# Watchdog register map
Vendor: Texas Instruments
Peripheral module from a debugger description file (folder am335x).
Registers are 32-bit, read-write, no defined reset value unless marked. A register's access mark holds for its fields unless they carry their own. Offsets are as the file gives them; lines under a group give offsets from that group; [hi:lo] are bit positions; {n}, {i} and the like mark numbered series; 'fields as' and 'values as' point back to an identical list; <NAME> marks a mode.

## WATCHDOG_TIMER
0x00 WDT_WIDR ro — Watchdog Identification Register
  [31:0] REVISION — IP Revision
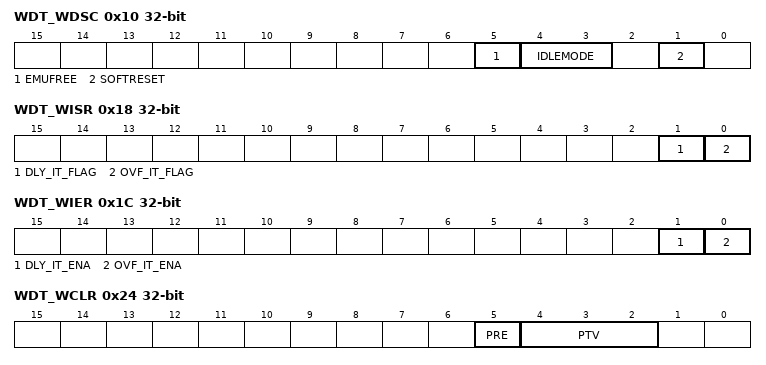
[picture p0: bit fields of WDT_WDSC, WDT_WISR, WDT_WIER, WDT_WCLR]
0x10 WDT_WDSC access per field — The Watchdog System Control Register controls the various parameters of the L4 interface.
  [5] EMUFREE rw — Emulation mode
  [4:3] IDLEMODE rw — Configuration of the local target state management mode.By definition, target can handle read/write transaction as long as it is out of IDLE state.
  [1] SOFTRESET rw — Software reset. (Optional)
0x14 WDT_WDST ro — The Watchdog Status Register provides status information about the module.
  [0] RESETDONE — Internal module reset monitoring
0x18 WDT_WISR access per field — The Watchdog Interrupt Status Register shows which interrupt events are pending inside the module.
  [1] DLY_IT_FLAG rw — Pending delay interrupt status.
  [0] OVF_IT_FLAG rw — Pending overflow interrupt status.
0x1C WDT_WIER access per field — The Watchdog Interrupt Enable Register controls (enable/disable) the interrupt events.
  [1] DLY_IT_ENA rw — Delay interrupt enable/disable
  [0] OVF_IT_ENA rw — Overflow interrupt enable/disable
0x24 WDT_WCLR access per field — The Watchdog Control Register controls the prescaler stage of the counter.
  [5] PRE rw — Prescaler enable/disable configuration
  [4:2] PTV rw — Prescaler value. The timer counter is prescaled with the value: 2**PTV. Example: PTV = 3 then counter increases value if started after 8 functional clock periods. On reset, it is loaded from PI_PTV_RESET_VALUE input port.
0x28 WDT_WCRR — The Watchdog Counter Register holds the value of the internal counter.
  [31:0] TIMER_COUNTER — Value of the timer counter register
0x2C WDT_WLDR — The Watchdog Load Register holds the timer load value.
  [31:0] TIMER_LOAD — Value of the timer load register
0x30 WDT_WTGR — Writing a different value than the one already written in the Watchdog Trigger Register does a watchdog counter reload.
  [31:0] TTGR_VALUE — Value of the trigger register
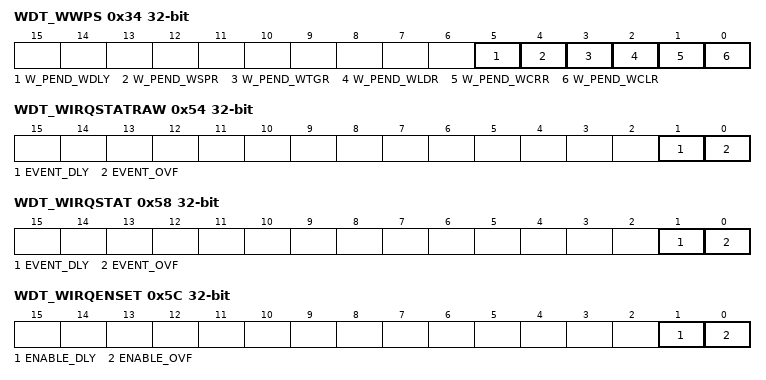
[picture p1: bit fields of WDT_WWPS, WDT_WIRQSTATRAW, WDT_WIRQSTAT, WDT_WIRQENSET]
0x34 WDT_WWPS ro — The Watchdog Write Posting Bits Register contains the write posting bits for all writeable functional registers.
  [5] W_PEND_WDLY — Write pending for register WDLY
  [4] W_PEND_WSPR — Write pending for register WSPR
  [3] W_PEND_WTGR — Write pending for register WTGR
  [2] W_PEND_WLDR — Write pending for register WLDR
  [1] W_PEND_WCRR — Write pending for register WCRR
  [0] W_PEND_WCLR — Write pending for register WCLR
0x44 WDT_WDLY — The Watchdog Delay Configuration Register holds the delay value that controls the internal pre-overflow event detection.
  [31:0] WDLY_VALUE — Value of the delay register
0x48 WDT_WSPR — The Watchdog Start/Stop Register holds the start-stop value that controls the internal start-stop FSM.
  [31:0] WSPR_VALUE — Value of the start-stop register
0x54 WDT_WIRQSTATRAW access not given — In the Watchdog Raw Interrupt Status Register, IRQ unmasked status, status set per-event raw interrupt status vector, line 0. Raw status is set even if event is not enabled. Write 1 to set the (raw) status, mostly for debug.
  [1] EVENT_DLY — Settable raw status for delay event (access R/W1S)
  [0] EVENT_OVF — Settable raw status for overflow event (access R/W1S)
0x58 WDT_WIRQSTAT access not given — In the Watchdog Interrupt Status Register, IRQ masked status, status clear per-event enabled interrupt status vector, line 0. Enabled status is not set unless event is enabled. Write 1 to clear the status after interrupt has been serviced (raw status gets cleared, that is, even if not enabled).
  [1] EVENT_DLY — Clearable, enabled status for delay event (access R/W1C)
  [0] EVENT_OVF — Clearable, enabled status for overflow event (access R/W1C)
0x5C WDT_WIRQENSET access not given — In the Watchdog Interrupt Enable Set Register, IRQ enable set per-event interrupt enable bit vector, line 0. Write 1 to set (enable interrupt). Readout equal to corresponding _CLR register.
  [1] ENABLE_DLY — Enable for delay event (access R/W1S)
  [0] ENABLE_OVF — Enable for overflow event (access R/W1S)
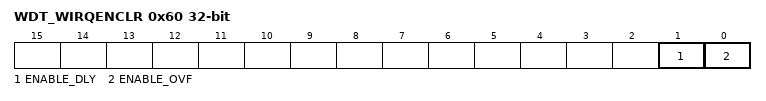
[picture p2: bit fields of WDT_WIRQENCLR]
0x60 WDT_WIRQENCLR access not given — In the Watchdog Interrupt Enable Clear Register, IRQ enable clear per-event interrupt enable bit vector, line 0. Write 1 to clear (disable interrupt). Readout equal to corresponding _SET register.
  [1] ENABLE_DLY — Enable for delay event (access R/W1C)
  [0] ENABLE_OVF — Enable for overflow event (access R/W1C)
